# pma_rx_lane_registers: IP-XACT component
VLNV cadence:cdns_lib:pma_rx_lane_registers:1685-2009

## Address spaces and blocks
sd3101_t4_registers.sd3101_phy_registers: base 0x20000, range 0x7ff, width 32

## Registers
Registers are 32-bit, read-write, reset 0x0 unless marked. A register's access mark holds for its fields unless they carry their own. Offsets are from the block's base; lines under a group give offsets from that group; [hi:lo] are bit positions; {n}, {i} and the like mark numbered series; 'fields as' and 'values as' point back to an identical list; <NAME> marks a mode.

## sd3101_t4_registers.sd3101_phy_registers
Base 0x00020000
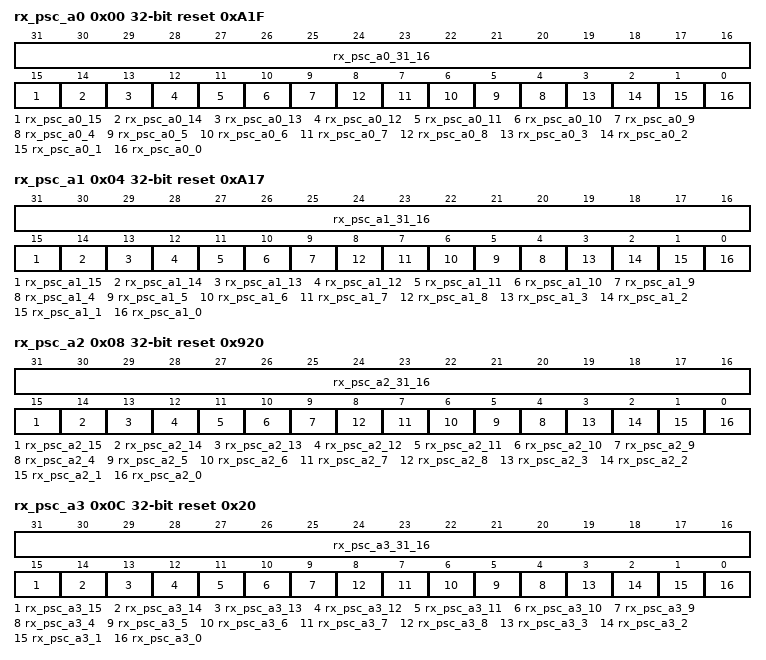
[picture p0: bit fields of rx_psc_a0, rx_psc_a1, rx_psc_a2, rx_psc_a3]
0x00 rx_psc_a0 reset 0xA1F — Receiver A0 power state definition register
  [31:16] rx_psc_a0_31_16 ro — Reserved
  [15] rx_psc_a0_15 ro — Reserved
  [14] rx_psc_a0_14 — rxda_dfe_error_threshold_pol
  [13] rx_psc_a0_13 — rxda_dfe_eq_tap1_pol
  [12] rx_psc_a0_12 — RX signal detect enable extend control
  [11] rx_psc_a0_11 — RX signal detect filter enable
  [10] rx_psc_a0_10
  [9] rx_psc_a0_9 — RX signal detect enable
  [n] rx_psc_a0_{n} (n=4..8) — rxda_dfe_eq_tap{n-3}_en
  [3] rx_psc_a0_3 — RX equalization functions enable
  [2] rx_psc_a0_2 — RX PI enable
  [1] rx_psc_a0_1 — RX e path enable
  [0] rx_psc_a0_0 — RX enable
0x04 rx_psc_a1 reset 0xA17 — Receiver A1 power state definition register
  [31:16] rx_psc_a1_31_16 ro — Reserved
  [15] rx_psc_a1_15 ro — Reserved
  [14] rx_psc_a1_14 — rxda_dfe_error_threshold_pol
  [13] rx_psc_a1_13 — rxda_dfe_eq_tap1_pol
  [12] rx_psc_a1_12 — RX signal detect enable extend control
  [11] rx_psc_a1_11 — RX signal detect filter enable
  [10] rx_psc_a1_10 — RX LFPS detect filter enable
  [9] rx_psc_a1_9 — RX signal detect enable
  [n] rx_psc_a1_{n} (n=4..8) — rxda_dfe_eq_tap{n-3}_en
  [3] rx_psc_a1_3 — RX equalization functions enable
  [2] rx_psc_a1_2 — RX PI enable
  [1] rx_psc_a1_1 — RX e path enable
  [0] rx_psc_a1_0 — RX enable
0x08 rx_psc_a2 reset 0x920 — Receiver A2 power state definition register
  [31:16] rx_psc_a2_31_16 ro — Reserved
  [15] rx_psc_a2_15 ro — Reserved
  [14] rx_psc_a2_14 — rxda_dfe_error_threshold_pol
  [13] rx_psc_a2_13 — rxda_dfe_eq_tap1_pol
  [12] rx_psc_a2_12 — RX signal detect enable extend control
  [11] rx_psc_a2_11 — RX signal detect filter enable
  [10] rx_psc_a2_10 — RX LFPS detect filter enable
  [9] rx_psc_a2_9 — RX signal detect enable
  [n] rx_psc_a2_{n} (n=4..8) — rxda_dfe_eq_tap{n-3}_en
  [3] rx_psc_a2_3 — RX equalization functions enable
  [2] rx_psc_a2_2 — RX PI enable
  [1] rx_psc_a2_1 — RX e path enable
  [0] rx_psc_a2_0 — RX enable
0x0C rx_psc_a3 reset 0x20 — Receiver A3 power state definition register
  [31:16] rx_psc_a3_31_16 ro — Reserved
  [15] rx_psc_a3_15 ro — Reserved
  [14] rx_psc_a3_14 — rxda_dfe_error_threshold_pol
  [13] rx_psc_a3_13 — rxda_dfe_eq_tap1_pol
  [12] rx_psc_a3_12 — RX signal detect enable extend control
  [11] rx_psc_a3_11 — RX signal detect filter enable
  [10] rx_psc_a3_10 — RX LFPS detect filter enable
  [9] rx_psc_a3_9 — RX signal detect enable
  [n] rx_psc_a3_{n} (n=4..8) — rxda_dfe_eq_tap{n-3}_en
  [3] rx_psc_a3_3 — RX equalization functions enable
  [2] rx_psc_a3_2 — RX PI enable
  [1] rx_psc_a3_1 — RX e path enable
  [0] rx_psc_a3_0 — RX enable
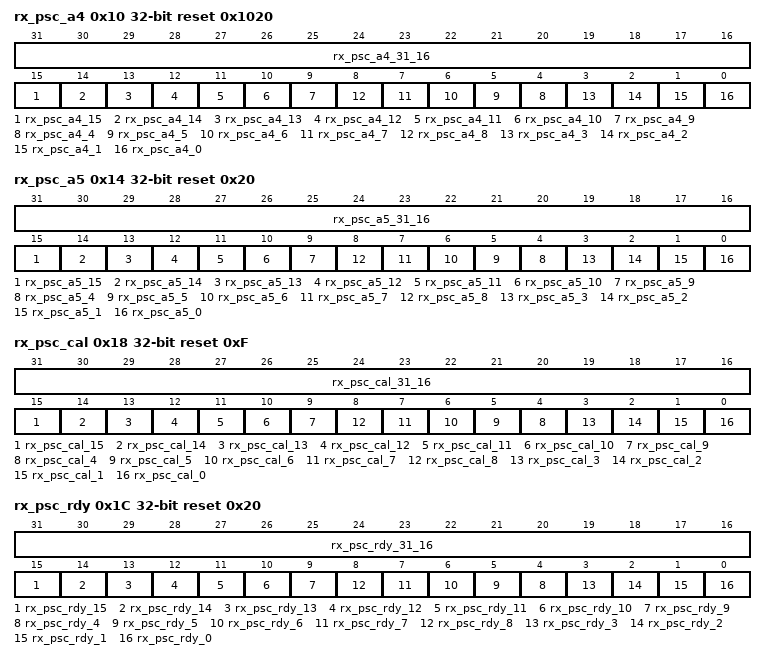
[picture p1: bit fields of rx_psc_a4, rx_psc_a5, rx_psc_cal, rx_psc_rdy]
0x10 rx_psc_a4 reset 0x1020 — Receiver A4 power state definition register
  [31:16] rx_psc_a4_31_16 ro — Reserved
  [15] rx_psc_a4_15 ro — Reserved
  [14] rx_psc_a4_14 — rxda_dfe_error_threshold_pol
  [13] rx_psc_a4_13 — rxda_dfe_eq_tap1_pol
  [12] rx_psc_a4_12 — RX signal detect enable extend control
  [11] rx_psc_a4_11 — RX signal detect filter enable
  [10] rx_psc_a4_10 — RX LFPS detect filter enable
  [9] rx_psc_a4_9 — RX signal detect enable
  [n] rx_psc_a4_{n} (n=4..8) — rxda_dfe_eq_tap{n-3}_en
  [3] rx_psc_a4_3 — RX equalization functions enable
  [2] rx_psc_a4_2 — RX PI enable
  [1] rx_psc_a4_1 — RX e path enable
  [0] rx_psc_a4_0 — RX enable
0x14 rx_psc_a5 reset 0x20 — Receiver A5 power state definition register
  [31:16] rx_psc_a5_31_16 ro — Reserved
  [15] rx_psc_a5_15 ro — Reserved
  [14] rx_psc_a5_14 — rxda_dfe_error_threshold_pol
  [13] rx_psc_a5_13 — rxda_dfe_eq_tap1_pol
  [12] rx_psc_a5_12 — RX signal detect enable extend control
  [11] rx_psc_a5_11 — RX signal detect filter enable
  [10] rx_psc_a5_10 — RX LFPS detect filter enable
  [9] rx_psc_a5_9 — RX signal detect enable
  [n] rx_psc_a5_{n} (n=4..8) — rxda_dfe_eq_tap{n-3}_en
  [3] rx_psc_a5_3 — RX equalization functions enable
  [2] rx_psc_a5_2 — RX PI enable
  [1] rx_psc_a5_1 — RX e path enable
  [0] rx_psc_a5_0 — RX enable
0x18 rx_psc_cal reset 0xF — Receiver calibration power state definition register
  [31:16] rx_psc_cal_31_16 ro — Reserved
  [15] rx_psc_cal_15 ro — Reserved
  [14] rx_psc_cal_14 — rxda_dfe_error_threshold_pol
  [13] rx_psc_cal_13 — rxda_dfe_eq_tap1_pol
  [12] rx_psc_cal_12 — RX signal detect enable extend control
  [11] rx_psc_cal_11 — RX signal detect filter enable
  [10] rx_psc_cal_10 — RX LFPS detect filter enable
  [9] rx_psc_cal_9 — RX signal detect enable
  [n] rx_psc_cal_{n} (n=4..8) — rxda_dfe_eq_tap{n-3}_en
  [3] rx_psc_cal_3 — RX equalization functions enable
  [2] rx_psc_cal_2 — RX PI enable
  [1] rx_psc_cal_1 — RX e path enable
  [0] rx_psc_cal_0 — RX enable
0x1C rx_psc_rdy reset 0x20 — Receiver ready power state definition register
  [31:16] rx_psc_rdy_31_16 ro — Reserved
  [15] rx_psc_rdy_15 ro — Reserved
  [14] rx_psc_rdy_14 — rxda_dfe_error_threshold_pol
  [13] rx_psc_rdy_13 — rxda_dfe_eq_tap1_pol
  [12] rx_psc_rdy_12 — RX signal detect enable extend control
  [11] rx_psc_rdy_11 — RX signal detect filter enable
  [10] rx_psc_rdy_10 — RX LFPS detect filter enable
  [9] rx_psc_rdy_9 — RX signal detect enable
  [n] rx_psc_rdy_{n} (n=4..8) — rxda_dfe_eq_tap{n-3}_en
  [3] rx_psc_rdy_3 — RX equalization functions enable
  [2] rx_psc_rdy_2 — RX PI enable
  [1] rx_psc_rdy_1 — RX e path enable
  [0] rx_psc_rdy_0 — RX enable
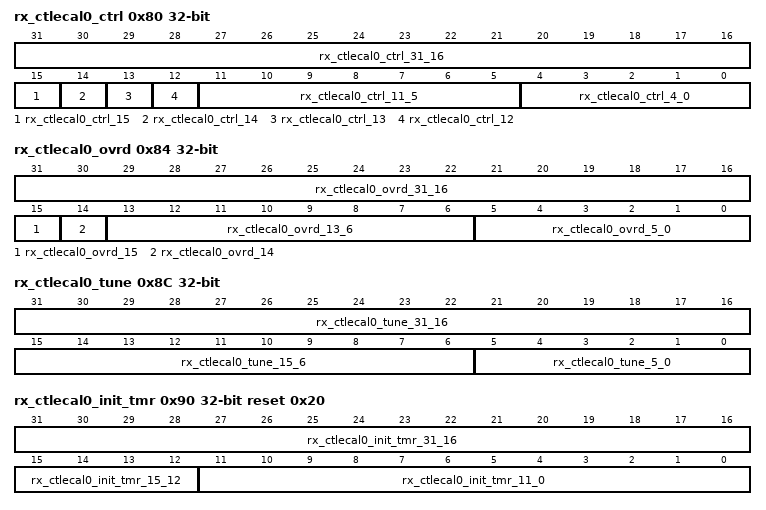
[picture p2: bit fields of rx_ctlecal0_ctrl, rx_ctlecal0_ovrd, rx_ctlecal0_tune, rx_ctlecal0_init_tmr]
0x80 rx_ctlecal0_ctrl — CTLE VGA offset calibration 0 control register
  [31:16] rx_ctlecal0_ctrl_31_16 ro — Reserved
  [15] rx_ctlecal0_ctrl_15 — Note: This bit is intended to be for diagnostics purposes only. This calibration process is automatically activated internally by the power state machine. When using this bit, the user must wait until after the internally activated process completes.
  [14] rx_ctlecal0_ctrl_14 ro — Note: Three cmn_ref_clk cycles are required after the start of the calibration process to clear this signal.
  [13] rx_ctlecal0_ctrl_13 ro — Note: Due to the nature of the calibration process, it is not possible to determine if the analog responded or not for the lowest code of 4'b1001. The reason for this is, when sequencing to lower codes, the calibration function is looking for the analog response to transition from 1'b1 to 1'b0. If the lowest calibration code is the correct code, the analog will respond with 1'b1, and the algorithm can't sequence to a lower code to look for the transition from 1'b1 to 1'b0. Similarly, if the analog is not responding, it is not possible to sequence to a lower code to detect this. Therefore, even when the calibration function selects this calibration code as valid, this bit will be set.
  [12] rx_ctlecal0_ctrl_12 ro
  [11:5] rx_ctlecal0_ctrl_11_5 ro — Reserved
  [4:0] rx_ctlecal0_ctrl_4_0 ro
0x84 rx_ctlecal0_ovrd — CTLE VGA offset calibration 0 override register
  [31:16] rx_ctlecal0_ovrd_31_16 ro — Reserved
  [15] rx_ctlecal0_ovrd_15 — Note: The value of this field must not be changed while the calibration function is running.
  [14] rx_ctlecal0_ovrd_14
  [13:6] rx_ctlecal0_ovrd_13_6 ro — Reserved
  [5:0] rx_ctlecal0_ovrd_5_0 — Note: The value of this field must not be changed while the calibration function is running.
0x8C rx_ctlecal0_tune — CTLE VGA offset calibration 0 tune register
  [31:16] rx_ctlecal0_tune_31_16 ro — Reserved
  [15:6] rx_ctlecal0_tune_15_6 ro — Reserved
  [5:0] rx_ctlecal0_tune_5_0 — Note: This value is a twos complement value, so the calibrated code can be increased or decreased.
0x90 rx_ctlecal0_init_tmr reset 0x20 — CTLE VGA offset calibration 0 initialization timer register
  [31:16] rx_ctlecal0_init_tmr_31_16 ro — Reserved
  [15:12] rx_ctlecal0_init_tmr_15_12 ro — Reserved
  [11:0] rx_ctlecal0_init_tmr_11_0 — Note: This results in the minimum number of cmn_ref_clk clocks required to wait 1 uSec. Note: This should never be set to a value of less than 1.
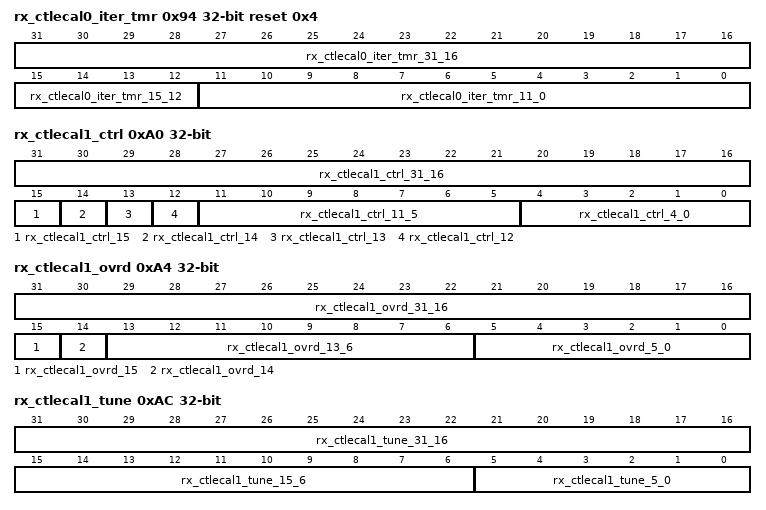
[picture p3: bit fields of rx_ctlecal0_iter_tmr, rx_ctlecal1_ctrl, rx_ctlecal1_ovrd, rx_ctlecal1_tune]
0x94 rx_ctlecal0_iter_tmr reset 0x4 — CTLE VGA offset calibration 0 iteration timer register
  [31:16] rx_ctlecal0_iter_tmr_31_16 ro — Reserved
  [15:12] rx_ctlecal0_iter_tmr_15_12 ro — Reserved
  [11:0] rx_ctlecal0_iter_tmr_11_0 — Note: This results in the minimum number of cmn_ref_clk clocks required to wait 5 uSec. Note: This should never be set to a value of less than 3.
0xA0 rx_ctlecal1_ctrl — CTLE VGA offset calibration 1 control register
  [31:16] rx_ctlecal1_ctrl_31_16 ro — Reserved
  [15] rx_ctlecal1_ctrl_15 — Note: This bit is intended to be for diagnostics purposes only. This calibration process is automatically activated internally by the power state machine. When using this bit, the user must wait until after the internally activated process completes.
  [14] rx_ctlecal1_ctrl_14 ro — Note: Three cmn_ref_clk cycles are required after the start of the calibration process to clear this signal.
  [13] rx_ctlecal1_ctrl_13 ro — Note: Due to the nature of the calibration process, it is not possible to determine if the analog responded or not for the lowest code of 4'b1001. The reason for this is, when sequencing to lower codes, the calibration function is looking for the analog response to transition from 1'b1 to 1'b0. If the lowest calibration code is the correct code, the analog will respond with 1'b1, and the algorithm can't sequence to a lower code to look for the transition from 1'b1 to 1'b0. Similarly, if the analog is not responding, it is not possible to sequence to a lower code to detect this. Therefore, even when the calibration function selects this calibration code as valid, this bit will be set.
  [12] rx_ctlecal1_ctrl_12 ro
  [11:5] rx_ctlecal1_ctrl_11_5 ro — Reserved
  [4:0] rx_ctlecal1_ctrl_4_0 ro
0xA4 rx_ctlecal1_ovrd — CTLE VGA offset calibration 1 override register
  [31:16] rx_ctlecal1_ovrd_31_16 ro — Reserved
  [15] rx_ctlecal1_ovrd_15 — Note: The value of this field must not be changed while the calibration function is running.
  [14] rx_ctlecal1_ovrd_14
  [13:6] rx_ctlecal1_ovrd_13_6 ro — Reserved
  [5:0] rx_ctlecal1_ovrd_5_0 — Note: The value of this field must not be changed while the calibration function is running.
0xAC rx_ctlecal1_tune — CTLE VGA offset calibration 1 tune register
  [31:16] rx_ctlecal1_tune_31_16 ro — Reserved
  [15:6] rx_ctlecal1_tune_15_6 ro — Reserved
  [5:0] rx_ctlecal1_tune_5_0 — Note: This value is a twos complement value, so the calibrated code can be increased or decreased.
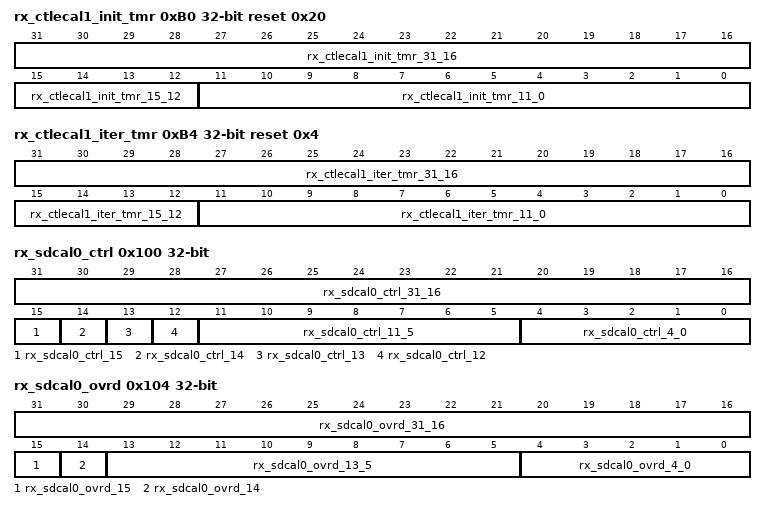
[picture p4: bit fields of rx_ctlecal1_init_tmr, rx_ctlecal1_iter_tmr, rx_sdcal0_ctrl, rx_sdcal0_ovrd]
0xB0 rx_ctlecal1_init_tmr reset 0x20 — CTLE VGA offset calibration 1 initialization timer register
  [31:16] rx_ctlecal1_init_tmr_31_16 ro — Reserved
  [15:12] rx_ctlecal1_init_tmr_15_12 ro — Reserved
  [11:0] rx_ctlecal1_init_tmr_11_0 — Note: This results in the minimum number of cmn_ref_clk clocks required to wait 1 uSec. Note: This should never be set to a value of less than 1.
0xB4 rx_ctlecal1_iter_tmr reset 0x4 — CTLE VGA offset calibration 1 iteration timer register
  [31:16] rx_ctlecal1_iter_tmr_31_16 ro — Reserved
  [15:12] rx_ctlecal1_iter_tmr_15_12 ro — Reserved
  [11:0] rx_ctlecal1_iter_tmr_11_0 — Note: This results in the minimum number of cmn_ref_clk clocks required to wait 5 uSec. Note: This should never be set to a value of less than 3.
0x100 rx_sdcal0_ctrl — Signal detect calibration 0 control register
  [31:16] rx_sdcal0_ctrl_31_16 ro — Reserved
  [15] rx_sdcal0_ctrl_15 — Note: This bit is intended to be for diagnostics purposes only. This calibration process is automatically activated internally by the power state machine. When using this bit, the user must wait until after the internally activated process completes.
  [14] rx_sdcal0_ctrl_14 ro — Note: Three cmn_ref_clk cycles are required after the start of the calibration process to clear this signal.
  [13] rx_sdcal0_ctrl_13 ro — Note: Due to the nature of the calibration process, it is not possible to determine if the analog responded or not for the lowest code of 4'b1001. The reason for this is, when sequencing to lower codes, the calibration function is looking for the analog response to transition from 1'b1 to 1'b0. If the lowest calibration code is the correct code, the analog will respond with 1'b1, and the algorithm can't sequence to a lower code to look for the transition from 1'b1 to 1'b0. Similarly, if the analog is not responding, it is not possible to sequence to a lower code to detect this. Therefore, even when the calibration function selects this calibration code as valid, this bit will be set.
  [12] rx_sdcal0_ctrl_12 ro
  [11:5] rx_sdcal0_ctrl_11_5 ro — Reserved
  [4:0] rx_sdcal0_ctrl_4_0 ro
0x104 rx_sdcal0_ovrd — Signal detect calibration 0 override register
  [31:16] rx_sdcal0_ovrd_31_16 ro — Reserved
  [15] rx_sdcal0_ovrd_15 — Note: The value of this field must not be changed while the calibration function is running.
  [14] rx_sdcal0_ovrd_14
  [13:5] rx_sdcal0_ovrd_13_5 ro — Reserved
  [4:0] rx_sdcal0_ovrd_4_0 — Note: The value of this field must not be changed while the calibration function is running.
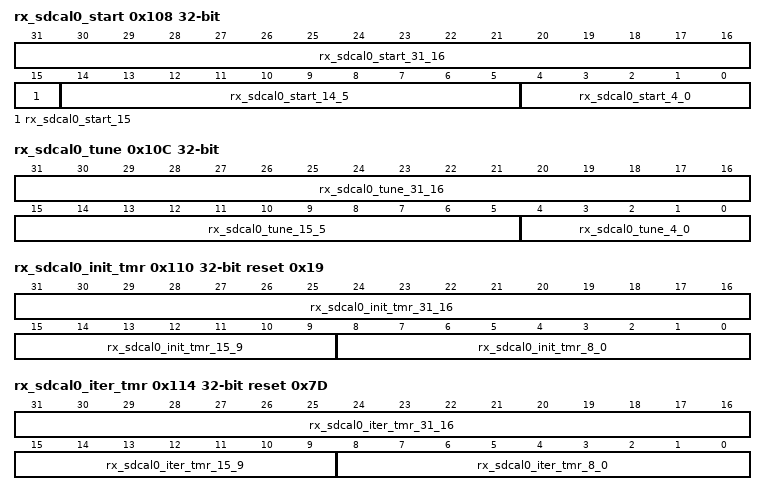
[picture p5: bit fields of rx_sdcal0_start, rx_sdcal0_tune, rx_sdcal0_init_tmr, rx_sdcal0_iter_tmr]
0x108 rx_sdcal0_start — Signal detect calibration 0 start register
  [31:16] rx_sdcal0_start_31_16 ro — Reserved
  [15] rx_sdcal0_start_15
  [14:5] rx_sdcal0_start_14_5 ro — Reserved
  [4:0] rx_sdcal0_start_4_0 — Start calibration code
0x10C rx_sdcal0_tune — Signal detect calibration 0 tune register
  [31:16] rx_sdcal0_tune_31_16 ro — Reserved
  [15:5] rx_sdcal0_tune_15_5 ro — Reserved
  [4:0] rx_sdcal0_tune_4_0 — Note: This value is a twos complement value, so the calibrated code can be increased or decreased.
0x110 rx_sdcal0_init_tmr reset 0x19 — Signal detect calibration 0 initialization timer register
  [31:16] rx_sdcal0_init_tmr_31_16 ro — Reserved
  [15:9] rx_sdcal0_init_tmr_15_9 ro — Reserved
  [8:0] rx_sdcal0_init_tmr_8_0 — Note: This results in the minimum number of cmn_ref_clk clocks required to wait 1 uSec. Note: This should never be set to a value of less than 1.
0x114 rx_sdcal0_iter_tmr reset 0x7D — Signal detect calibration 0 iteration timer register
  [31:16] rx_sdcal0_iter_tmr_31_16 ro — Reserved
  [15:9] rx_sdcal0_iter_tmr_15_9 ro — Reserved
  [8:0] rx_sdcal0_iter_tmr_8_0 — Note: This results in the minimum number of cmn_ref_clk clocks required to wait 5 uSec. Note: This should never be set to a value of less than 3.
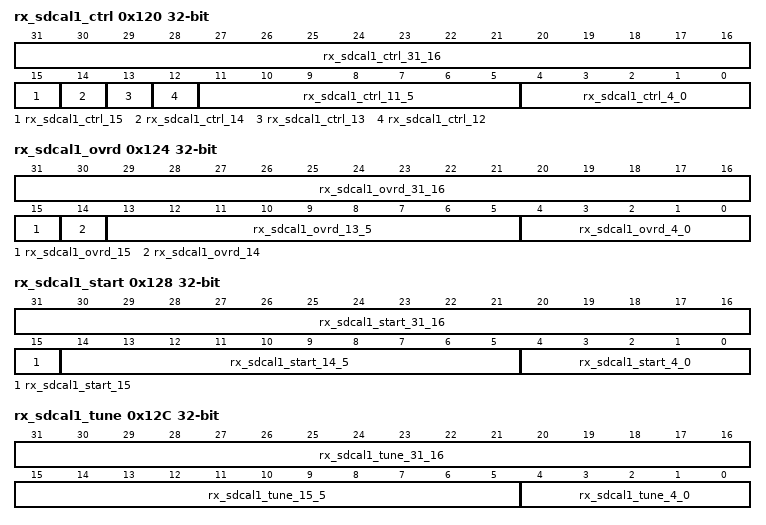
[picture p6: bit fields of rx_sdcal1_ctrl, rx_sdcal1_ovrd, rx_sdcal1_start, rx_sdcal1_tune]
0x120 rx_sdcal1_ctrl — Signal detect calibration 1 control register
  [31:16] rx_sdcal1_ctrl_31_16 ro — Reserved
  [15] rx_sdcal1_ctrl_15 — Note: This bit is intended to be for diagnostics purposes only. This calibration process is automatically activated internally by the power state machine. When using this bit, the user must wait until after the internally activated process completes.
  [14] rx_sdcal1_ctrl_14 ro — Note: Three cmn_ref_clk cycles are required after the start of the calibration process to clear this signal.
  [13] rx_sdcal1_ctrl_13 ro — Note: Due to the nature of the calibration process, it is not possible to determine if the analog responded or not for the lowest code of 4'b1001. The reason for this is, when sequencing to lower codes, the calibration function is looking for the analog response to transition from 1'b1 to 1'b0. If the lowest calibration code is the correct code, the analog will respond with 1'b1, and the algorithm can't sequence to a lower code to look for the transition from 1'b1 to 1'b0. Similarly, if the analog is not responding, it is not possible to sequence to a lower code to detect this. Therefore, even when the calibration function selects this calibration code as valid, this bit will be set.
  [12] rx_sdcal1_ctrl_12 ro
  [11:5] rx_sdcal1_ctrl_11_5 ro — Reserved
  [4:0] rx_sdcal1_ctrl_4_0 ro
0x124 rx_sdcal1_ovrd — Signal detect calibration 1 override register
  [31:16] rx_sdcal1_ovrd_31_16 ro — Reserved
  [15] rx_sdcal1_ovrd_15 — Note: The value of this field must not be changed while the calibration function is running.
  [14] rx_sdcal1_ovrd_14
  [13:5] rx_sdcal1_ovrd_13_5 ro — Reserved
  [4:0] rx_sdcal1_ovrd_4_0 — Note: The value of this field must not be changed while the calibration function is running.
0x128 rx_sdcal1_start — Signal detect calibration 1 start register
  [31:16] rx_sdcal1_start_31_16 ro — Reserved
  [15] rx_sdcal1_start_15
  [14:5] rx_sdcal1_start_14_5 ro — Reserved
  [4:0] rx_sdcal1_start_4_0 — Start calibration code
0x12C rx_sdcal1_tune — Signal detect calibration 1 tune register
  [31:16] rx_sdcal1_tune_31_16 ro — Reserved
  [15:5] rx_sdcal1_tune_15_5 ro — Reserved
  [4:0] rx_sdcal1_tune_4_0 — Note: This value is a twos complement value, so the calibrated code can be increased or decreased.
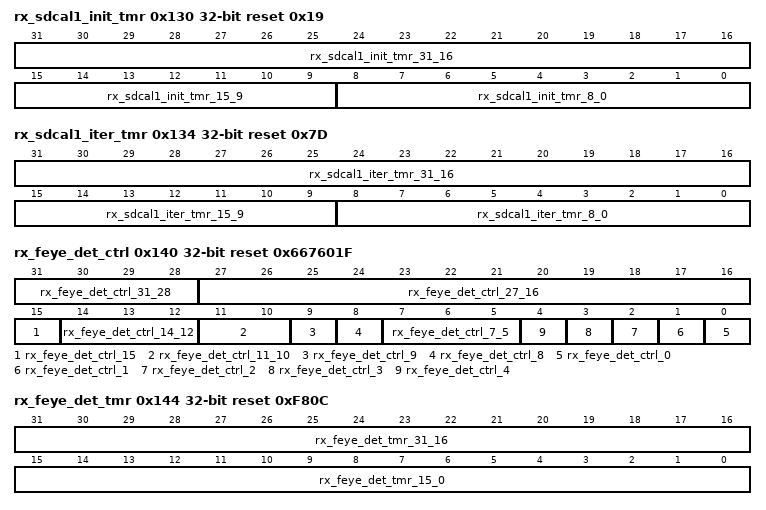
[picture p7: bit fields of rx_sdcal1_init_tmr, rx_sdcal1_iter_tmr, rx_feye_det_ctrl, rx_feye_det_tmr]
0x130 rx_sdcal1_init_tmr reset 0x19 — Signal detect calibration 1 initialization timer register
  [31:16] rx_sdcal1_init_tmr_31_16 ro — Reserved
  [15:9] rx_sdcal1_init_tmr_15_9 ro — Reserved
  [8:0] rx_sdcal1_init_tmr_8_0 — Note: This results in the minimum number of cmn_ref_clk clocks required to wait 1 uSec. Note: This should never be set to a value of less than 1.
0x134 rx_sdcal1_iter_tmr reset 0x7D — Signal detect calibration 1 iteration timer register
  [31:16] rx_sdcal1_iter_tmr_31_16 ro — Reserved
  [15:9] rx_sdcal1_iter_tmr_15_9 ro — Reserved
  [8:0] rx_sdcal1_iter_tmr_8_0 — Note: This results in the minimum number of cmn_ref_clk clocks required to wait 5 uSec. Note: This should never be set to a value of less than 3.
0x140 rx_feye_det_ctrl reset 0x667601F — RX false eye detect control register
  [31:28] rx_feye_det_ctrl_31_28 ro — Reserved
  [27:16] rx_feye_det_ctrl_27_16 — Threshold counter value
  [15] rx_feye_det_ctrl_15 ro — Reserved
  [14:12] rx_feye_det_ctrl_14_12 — Bandwidth
  [11:10] rx_feye_det_ctrl_11_10 ro — Reserved
  [9] rx_feye_det_ctrl_9 — Clear false eye detected
  [8] rx_feye_det_ctrl_8 ro
  [7:5] rx_feye_det_ctrl_7_5 ro — Reserved
  [n] rx_feye_det_ctrl_{n} (n=0..4)
0x144 rx_feye_det_tmr reset 0xF80C — RX false eye detect timer register
  [31:16] rx_feye_det_tmr_31_16 ro — Reserved
  [15:0] rx_feye_det_tmr_15_0
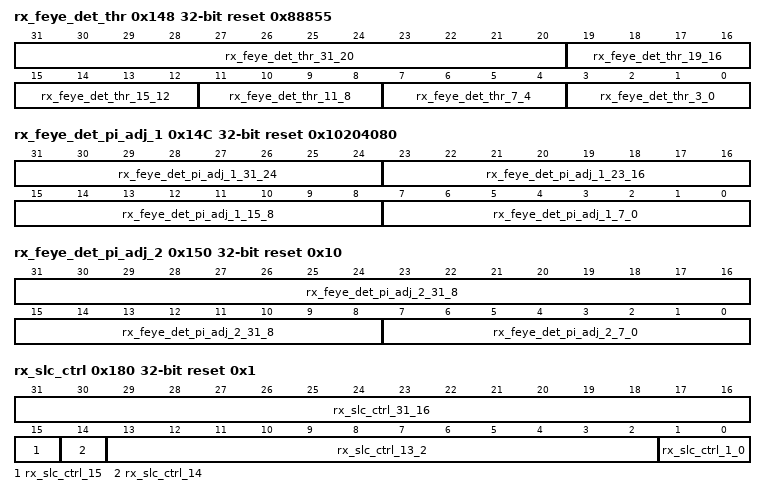
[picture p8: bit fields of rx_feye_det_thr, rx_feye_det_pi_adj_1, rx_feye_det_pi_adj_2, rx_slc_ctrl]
0x148 rx_feye_det_thr reset 0x88855 — RX false eye detect threshold register
  [31:20] rx_feye_det_thr_31_20 ro — Reserved
  [19:16] rx_feye_det_thr_19_16 — Threshold value standard mode 4
  [15:12] rx_feye_det_thr_15_12
  [11:8] rx_feye_det_thr_11_8 — Threshold value standard mode 2
  [7:4] rx_feye_det_thr_7_4 — Threshold value standard mode 1
  [3:0] rx_feye_det_thr_3_0
0x14C rx_feye_det_pi_adj_1 reset 0x10204080 — RX false eye detect PI adjust register 1
  [31:24] rx_feye_det_pi_adj_1_31_24 — PI adjust count standard mode 3
  [23:16] rx_feye_det_pi_adj_1_23_16
  [15:8] rx_feye_det_pi_adj_1_15_8 — PI adjust count standard mode 1
  [7:0] rx_feye_det_pi_adj_1_7_0 — PI adjust count standard mode 0
0x150 rx_feye_det_pi_adj_2 reset 0x10 — RX false eye detect PI adjust register 2
  [31:8] rx_feye_det_pi_adj_2_31_8 ro — Reserved
  [7:0] rx_feye_det_pi_adj_2_7_0 — PI adjust count standard mode 4
0x180 rx_slc_ctrl reset 0x1 — RX sampler latch calibration control register (!)
  [31:16] rx_slc_ctrl_31_16 — Reserved
  [15] rx_slc_ctrl_15
  [14] rx_slc_ctrl_14 ro
  [13:2] rx_slc_ctrl_13_2 ro — Reserved
  [1:0] rx_slc_ctrl_1_0
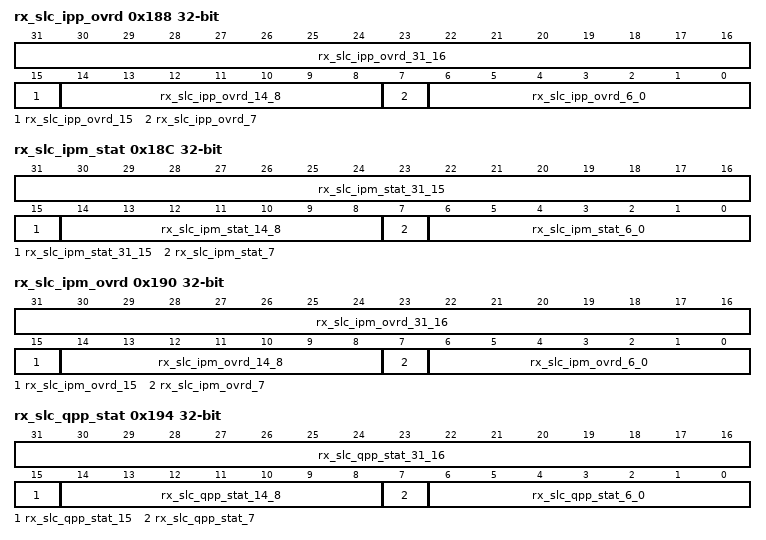
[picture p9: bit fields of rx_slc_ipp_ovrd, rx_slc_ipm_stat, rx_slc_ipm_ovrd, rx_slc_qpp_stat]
0x188 rx_slc_ipp_ovrd — RX sampler latch calibration I predictive positive override register (!)
  [31:16] rx_slc_ipp_ovrd_31_16 — Reserved
  [15] rx_slc_ipp_ovrd_15
  [14:8] rx_slc_ipp_ovrd_14_8 — Note: The value of this field is a signed magnitude number with a range of 5'b11111 (min) to 5'b01111 (max). A value of 5'b10000 (-0) is not valid.
  [7] rx_slc_ipp_ovrd_7
  [6:0] rx_slc_ipp_ovrd_6_0 — Note: The value of this field is a signed magnitude number with a range of 5'b11111 (min) to 5'b01111 (max). A value of 5'b10000 (-0) is not valid.
0x18C rx_slc_ipm_stat — RX sampler latch calibration I predictive negative status register
  [31:15] rx_slc_ipm_stat_31_15 ro — Reserved
  [14:8] rx_slc_ipm_stat_14_8 ro
  [7] rx_slc_ipm_stat_7 ro — Reserved
  [6:0] rx_slc_ipm_stat_6_0 ro
0x190 rx_slc_ipm_ovrd — RX sampler latch calibration I predictive negative override register
  [31:16] rx_slc_ipm_ovrd_31_16 ro — Reserved
  [15] rx_slc_ipm_ovrd_15
  [14:8] rx_slc_ipm_ovrd_14_8 — Note: The value of this field is a signed magnitude number with a range of 5'b11111 (min) to 5'b01111 (max). A value of 5'b10000 (-0) is not valid.
  [7] rx_slc_ipm_ovrd_7
  [6:0] rx_slc_ipm_ovrd_6_0 — Note: The value of this field is a signed magnitude number with a range of 5'b11111 (min) to 5'b01111 (max). A value of 5'b10000 (-0) is not valid.
0x194 rx_slc_qpp_stat — RX sampler latch calibration Q predictive positive status register
  [31:16] rx_slc_qpp_stat_31_16 ro — Reserved
  [15] rx_slc_qpp_stat_15 ro — Reserved
  [14:8] rx_slc_qpp_stat_14_8 ro
  [7] rx_slc_qpp_stat_7 ro — Reserved
  [6:0] rx_slc_qpp_stat_6_0 ro
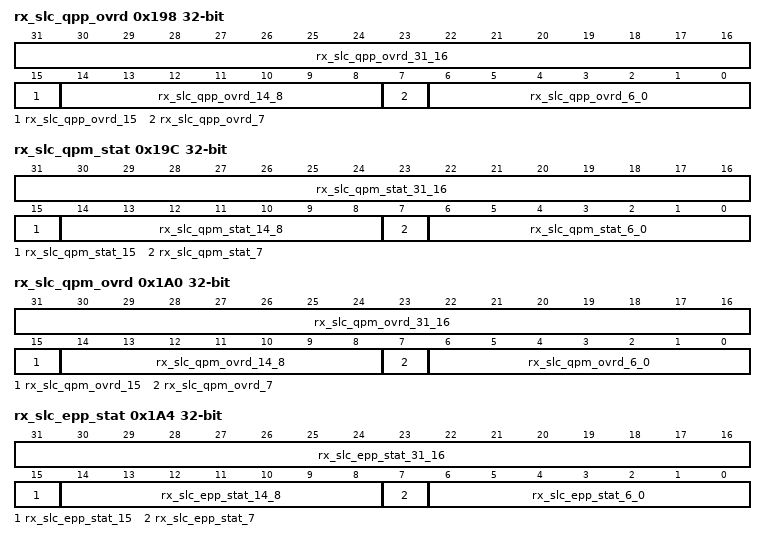
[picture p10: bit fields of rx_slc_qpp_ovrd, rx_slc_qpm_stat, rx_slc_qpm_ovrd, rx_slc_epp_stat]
0x198 rx_slc_qpp_ovrd — RX sampler latch calibration Q predictive positive override register
  [31:16] rx_slc_qpp_ovrd_31_16 ro — Reserved
  [15] rx_slc_qpp_ovrd_15
  [14:8] rx_slc_qpp_ovrd_14_8 — Note: The value of this field is a signed magnitude number with a range of 5'b11111 (min) to 5'b01111 (max). A value of 5'b10000 (-0) is not valid.
  [7] rx_slc_qpp_ovrd_7
  [6:0] rx_slc_qpp_ovrd_6_0 — Note: The value of this field is a signed magnitude number with a range of 5'b11111 (min) to 5'b01111 (max). A value of 5'b10000 (-0) is not valid.
0x19C rx_slc_qpm_stat — RX sampler latch calibration Q predictive negative status register
  [31:16] rx_slc_qpm_stat_31_16 ro — Reserved
  [15] rx_slc_qpm_stat_15 ro — Reserved
  [14:8] rx_slc_qpm_stat_14_8 ro
  [7] rx_slc_qpm_stat_7 ro — Reserved
  [6:0] rx_slc_qpm_stat_6_0 ro
0x1A0 rx_slc_qpm_ovrd — RX sampler latch calibration Q predictive negative override register
  [31:16] rx_slc_qpm_ovrd_31_16 ro — Reserved
  [15] rx_slc_qpm_ovrd_15
  [14:8] rx_slc_qpm_ovrd_14_8 — Note: The value of this field is a signed magnitude number with a range of 5'b11111 (min) to 5'b01111 (max). A value of 5'b10000 (-0) is not valid.
  [7] rx_slc_qpm_ovrd_7
  [6:0] rx_slc_qpm_ovrd_6_0 — Note: The value of this field is a signed magnitude number with a range of 5'b11111 (min) to 5'b01111 (max). A value of 5'b10000 (-0) is not valid.
0x1A4 rx_slc_epp_stat — RX sampler latch calibration e predictive positive status register
  [31:16] rx_slc_epp_stat_31_16 ro — Reserved
  [15] rx_slc_epp_stat_15 ro — Reserved
  [14:8] rx_slc_epp_stat_14_8 ro
  [7] rx_slc_epp_stat_7 ro — Reserved
  [6:0] rx_slc_epp_stat_6_0 ro
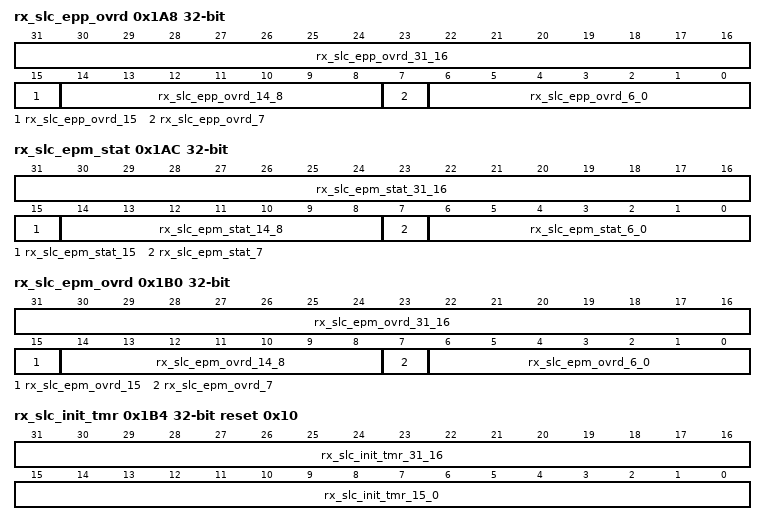
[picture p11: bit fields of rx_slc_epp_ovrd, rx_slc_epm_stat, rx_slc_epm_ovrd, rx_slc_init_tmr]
0x1A8 rx_slc_epp_ovrd — RX sampler latch calibration e predictive positive override register
  [31:16] rx_slc_epp_ovrd_31_16 ro — Reserved
  [15] rx_slc_epp_ovrd_15
  [14:8] rx_slc_epp_ovrd_14_8 — Note: The value of this field is a signed magnitude number with a range of 5'b11111 (min) to 5'b01111 (max). A value of 5'b10000 (-0) is not valid.
  [7] rx_slc_epp_ovrd_7
  [6:0] rx_slc_epp_ovrd_6_0 — Note: The value of this field is a signed magnitude number with a range of 5'b11111 (min) to 5'b01111 (max). A value of 5'b10000 (-0) is not valid.
0x1AC rx_slc_epm_stat — RX sampler latch calibration e predictive negative status register
  [31:16] rx_slc_epm_stat_31_16 ro — Reserved
  [15] rx_slc_epm_stat_15 ro — Reserved
  [14:8] rx_slc_epm_stat_14_8 ro
  [7] rx_slc_epm_stat_7 ro — Reserved
  [6:0] rx_slc_epm_stat_6_0 ro
0x1B0 rx_slc_epm_ovrd — RX sampler latch calibration e predictive negative override register
  [31:16] rx_slc_epm_ovrd_31_16 ro — Reserved
  [15] rx_slc_epm_ovrd_15
  [14:8] rx_slc_epm_ovrd_14_8 — Note: The value of this field is a signed magnitude number with a range of 5'b11111 (min) to 5'b01111 (max). A value of 5'b10000 (-0) is not valid.
  [7] rx_slc_epm_ovrd_7
  [6:0] rx_slc_epm_ovrd_6_0 — Note: The value of this field is a signed magnitude number with a range of 5'b11111 (min) to 5'b01111 (max). A value of 5'b10000 (-0) is not valid.
0x1B4 rx_slc_init_tmr reset 0x10 — RX sampler latch calibration initialization timer value register
  [31:16] rx_slc_init_tmr_31_16 ro — Reserved
  [15:0] rx_slc_init_tmr_15_0 — Note: This register should not be set to 16'h0000.
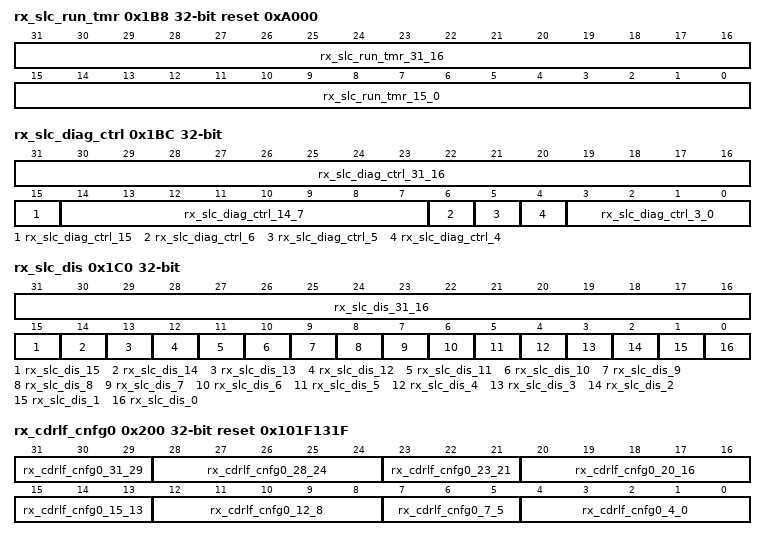
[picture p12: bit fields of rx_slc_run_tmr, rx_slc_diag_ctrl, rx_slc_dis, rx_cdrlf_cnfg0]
0x1B8 rx_slc_run_tmr reset 0xA000 — RX sampler latch calibration run timer value register
  [31:16] rx_slc_run_tmr_31_16 ro — Reserved
  [15:0] rx_slc_run_tmr_15_0 — Cadence internal note: The run timer value was changed to such a much longer time to allow for longer averaging, because of concerns the analog team has with regards to thermal noise. Significant variations of calibration codes were observed during lab characterization. It was shown in simulations that this was likely due to lower noise frequencies. Extending the run time has been shown to address the issue.
0x1BC rx_slc_diag_ctrl — RX sampler latch calibration diagnostic control register
  [31:16] rx_slc_diag_ctrl_31_16 ro — Reserved
  [15] rx_slc_diag_ctrl_15
  [14:7] rx_slc_diag_ctrl_14_7 ro — Reserved
  [6] rx_slc_diag_ctrl_6
  [5] rx_slc_diag_ctrl_5
  [4] rx_slc_diag_ctrl_4
  [3:0] rx_slc_diag_ctrl_3_0
0x1C0 rx_slc_dis — RX sampler latch calibration disable register
  [31:16] rx_slc_dis_31_16 ro — Reserved
  [15] rx_slc_dis_15 ro — Reserved
  [14] rx_slc_dis_14 — e even negative coefficient disable :
  [13] rx_slc_dis_13 — q even negative coefficient disable :
  [12] rx_slc_dis_12 — i even negative coefficient disable :
  [11] rx_slc_dis_11 ro — Reserved
  [10] rx_slc_dis_10 — e even positive coefficient disable :
  [9] rx_slc_dis_9 — q even positive coefficient disable :
  [8] rx_slc_dis_8 — i even positive coefficient disable :
  [7] rx_slc_dis_7 ro — Reserved
  [6] rx_slc_dis_6 — e odd negative coefficient disable :
  [5] rx_slc_dis_5 — q odd negative coefficient disable :
  [4] rx_slc_dis_4 — i odd negative coefficient disable :
  [3] rx_slc_dis_3 ro — Reserved
  [2] rx_slc_dis_2 — e odd positive coefficient disable :
  [1] rx_slc_dis_1 — q odd positive coefficient disable :
  [0] rx_slc_dis_0 — i odd positive coefficient disable :
0x200 rx_cdrlf_cnfg0 reset 0x101F131F — CDRLF configuration register 0
  [31:29] rx_cdrlf_cnfg0_31_29 ro — Reserved
  [28:24] rx_cdrlf_cnfg0_28_24 — CDRLF first order loop sigma delta update rate standard mode 3
  [23:21] rx_cdrlf_cnfg0_23_21 ro — Reserved
  [20:16] rx_cdrlf_cnfg0_20_16 — CDRLF first order loop sigma delta update rate standard mode 2
  [15:13] rx_cdrlf_cnfg0_15_13 ro — Reserved
  [12:8] rx_cdrlf_cnfg0_12_8 — CDRLF first order loop sigma delta update rate standard mode 1
  [7:5] rx_cdrlf_cnfg0_7_5 ro — Reserved
  [4:0] rx_cdrlf_cnfg0_4_0 — CDRLF first order loop sigma delta update rate standard mode 0
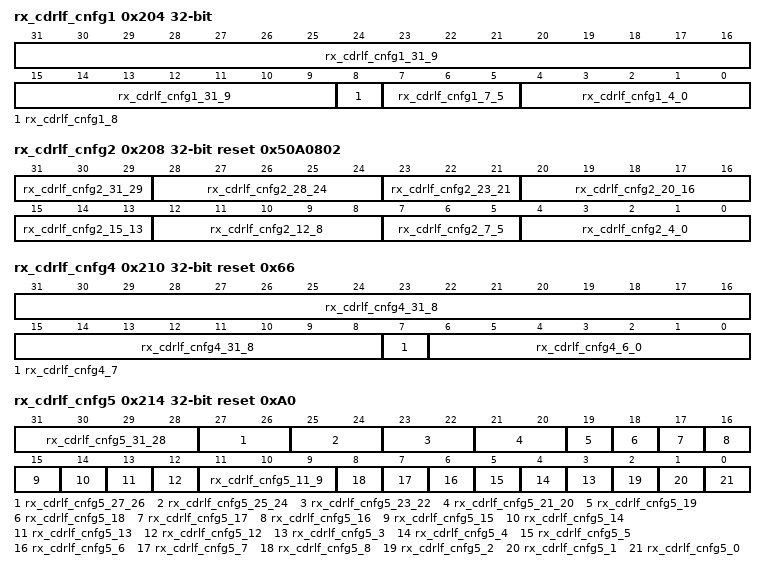
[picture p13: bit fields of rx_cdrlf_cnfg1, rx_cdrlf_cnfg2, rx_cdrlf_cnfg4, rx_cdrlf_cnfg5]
0x204 rx_cdrlf_cnfg1 — CDRLF configuration register 1
  [31:9] rx_cdrlf_cnfg1_31_9 ro — Reserved
  [8] rx_cdrlf_cnfg1_8 — rxda_iq_offset_load_pulse :
  [7:5] rx_cdrlf_cnfg1_7_5 ro — Reserved
  [4:0] rx_cdrlf_cnfg1_4_0
0x208 rx_cdrlf_cnfg2 reset 0x50A0802 — CDRLF configuration register 2
  [31:29] rx_cdrlf_cnfg2_31_29 ro — Reserved
  [28:24] rx_cdrlf_cnfg2_28_24
  [23:21] rx_cdrlf_cnfg2_23_21 ro — Reserved
  [20:16] rx_cdrlf_cnfg2_20_16 — CDRLF second order loop sigma delta update rate standard mode 2
  [15:13] rx_cdrlf_cnfg2_15_13 ro — Reserved
  [12:8] rx_cdrlf_cnfg2_12_8 — CDRLF second order loop sigma delta update rate standard mode 1
  [7:5] rx_cdrlf_cnfg2_7_5 ro — Reserved
  [4:0] rx_cdrlf_cnfg2_4_0
0x210 rx_cdrlf_cnfg4 reset 0x66 — CDRLF configuration register 4
  [31:8] rx_cdrlf_cnfg4_31_8 ro — Reserved
  [7] rx_cdrlf_cnfg4_7 ro — Reserved
  [6:0] rx_cdrlf_cnfg4_6_0 — Note: This field must never be set to a value less than 2 (6'b000010).
0x214 rx_cdrlf_cnfg5 reset 0xA0 — Note: Writing this register will result in wait states, in order to allow the values to be propagated to and sampled in the analog.
  [31:28] rx_cdrlf_cnfg5_31_28 ro — Reserved
  [27:26] rx_cdrlf_cnfg5_27_26
  [25:24] rx_cdrlf_cnfg5_25_24
  [23:22] rx_cdrlf_cnfg5_23_22
  [21:20] rx_cdrlf_cnfg5_21_20
  [19] rx_cdrlf_cnfg5_19 ro — Reserved
  [18] rx_cdrlf_cnfg5_18 wo — Note : This bit will be automatically cleared after the down request has been sent to the CDRLF IQ PI inter- face logic. The down request is generated by changing the state of the cdrlf_pi_down_in signal in the CDRLF.
  [17] rx_cdrlf_cnfg5_17 wo — Note : This bit will be automatically cleared after the up request has been sent to the CDRLF IQ PI interface logic. The up request is generated by changing the state of the cdrlf_pi_up_in signal in the CDRLF.
  [16] rx_cdrlf_cnfg5_16
  [15] rx_cdrlf_cnfg5_15 ro — Reserved
  [14] rx_cdrlf_cnfg5_14 wo — Note : This bit will be automatically cleared after the down request has been sent to the CDRLF PI inter- face logic.
  [13] rx_cdrlf_cnfg5_13 wo — Note : This bit will be automatically cleared after the up request has been sent to the CDRLF PI interface logic.
  [12] rx_cdrlf_cnfg5_12
  [11:9] rx_cdrlf_cnfg5_11_9 ro — Reserved
  [n] rx_cdrlf_cnfg5_{n} (n=3..8)
  [2] rx_cdrlf_cnfg5_2 — Note: This signal is intended be for verification purposes only. It should be set to 1'b0 for normal operation.
  [1] rx_cdrlf_cnfg5_1 — Note: This signal is intended be for verification purposes only. It should be set to 1'b0 for normal operation.
  [0] rx_cdrlf_cnfg5_0 — Note: This signal is intended be for verification purposes only. It should be set to 1'b0 for normal operation.
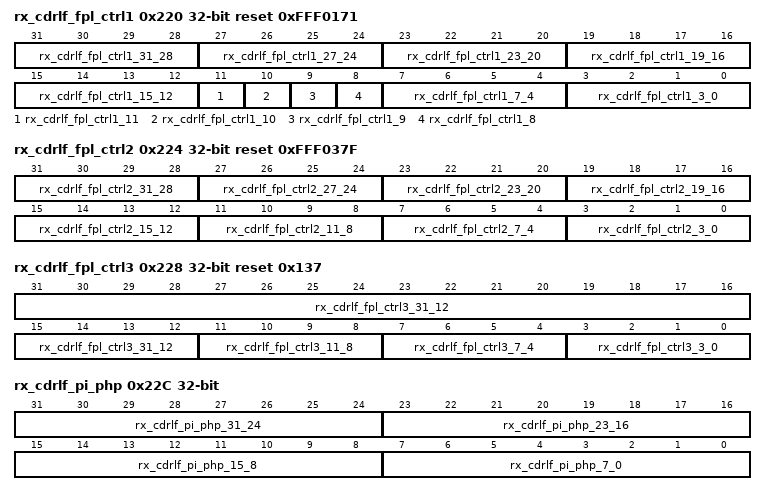
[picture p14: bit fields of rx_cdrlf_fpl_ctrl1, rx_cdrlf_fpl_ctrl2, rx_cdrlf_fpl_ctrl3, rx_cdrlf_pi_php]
0x220 rx_cdrlf_fpl_ctrl1 reset 0xFFF0171 — CDRLF fast phase lock control 1 register
  [31:28] rx_cdrlf_fpl_ctrl1_31_28 ro — Reserved
  [27:24] rx_cdrlf_fpl_ctrl1_27_24 — Fast phase lock timer trigger 3 state time value standard mode 0
  [23:20] rx_cdrlf_fpl_ctrl1_23_20 — Fast phase lock timer trigger 2 state time value standard mode 0
  [19:16] rx_cdrlf_fpl_ctrl1_19_16 — Fast phase lock timer trigger 1 state time value standard mode 0
  [15:12] rx_cdrlf_fpl_ctrl1_15_12 ro — Reserved
  [11] rx_cdrlf_fpl_ctrl1_11 ro — Reserved
  [10] rx_cdrlf_fpl_ctrl1_10 ro — CDRLF fast phase lock locked detected:
  [9] rx_cdrlf_fpl_ctrl1_9
  [8] rx_cdrlf_fpl_ctrl1_8 — CDRLF fast phase lock enabled by signal detect
  [7:4] rx_cdrlf_fpl_ctrl1_7_4 — Fast phase lock timer accumulate state time value
  [3:0] rx_cdrlf_fpl_ctrl1_3_0 — Fast phase lock timer delay state time value
0x224 rx_cdrlf_fpl_ctrl2 reset 0xFFF037F — CDRLF fast phase lock control 2 register
  [31:28] rx_cdrlf_fpl_ctrl2_31_28 ro — Reserved
  [27:24] rx_cdrlf_fpl_ctrl2_27_24
  [23:20] rx_cdrlf_fpl_ctrl2_23_20
  [19:16] rx_cdrlf_fpl_ctrl2_19_16
  [15:12] rx_cdrlf_fpl_ctrl2_15_12 ro — Reserved
  [11:8] rx_cdrlf_fpl_ctrl2_11_8
  [7:4] rx_cdrlf_fpl_ctrl2_7_4
  [3:0] rx_cdrlf_fpl_ctrl2_3_0
0x228 rx_cdrlf_fpl_ctrl3 reset 0x137 — CDRLF fast phase lock control 3 register
  [31:12] rx_cdrlf_fpl_ctrl3_31_12 ro — Reserved
  [11:8] rx_cdrlf_fpl_ctrl3_11_8
  [7:4] rx_cdrlf_fpl_ctrl3_7_4
  [3:0] rx_cdrlf_fpl_ctrl3_3_0
0x22C rx_cdrlf_pi_php — Note: The information read in this register is retrieved from another clock domain. Reading this register will result in wait states, in order to allow the control and data to cross the clock domains and be stable such that it can be accurately read.
  [31:24] rx_cdrlf_pi_php_31_24 ro — Reserved
  [23:16] rx_cdrlf_pi_php_23_16 ro — I PI phase position value
  [15:8] rx_cdrlf_pi_php_15_8 ro — Q PI phase position value
  [7:0] rx_cdrlf_pi_php_7_0 ro — E PI phase position value
0x230 rx_cdrlf_2ol_gain — Note: The information read in this register is retrieved from another clock domain. Reading this register will result in wait states, in order to allow the control and data to cross the clock domains and be stable such that it can be accurately read.
  [31:16] rx_cdrlf_2ol_gain_31_16 ro — Reserved
  [15:8] rx_cdrlf_2ol_gain_15_8 ro — Reserved
  [7:0] rx_cdrlf_2ol_gain_7_0 ro — Second order loop gain value
0x280 rx_eyesurf_ctrl — Eye surf control register
  [31] rx_eyesurf_ctrl_31
  [30] rx_eyesurf_ctrl_30 ro — Eye surf done
  [29:28] rx_eyesurf_ctrl_29_28 ro — Reserved
  [27:26] rx_eyesurf_ctrl_27_26 ro — Reserved
  [25] rx_eyesurf_ctrl_25 — Reserved - Spare
  [24] rx_eyesurf_ctrl_24
  [23:16] rx_eyesurf_ctrl_23_16 — Note : It is not valid to set this field to 0.
  [15:8] rx_eyesurf_ctrl_15_8 ro — Reserved
  [7:2] rx_eyesurf_ctrl_7_2 ro — Reserved
  [1] rx_eyesurf_ctrl_1
  [0] rx_eyesurf_ctrl_0
0x284 rx_eyesurf_tmr_test — Eye surf timer test register
  [31:0] rx_eyesurf_tmr_test_31_0 — Note : It is not valid to set this field to 0.
0x288 rx_eyesurf_offset — Eye surf test point offset register
  [31:17] rx_eyesurf_offset_31_17 ro — Reserved
  [16] rx_eyesurf_offset_16
  [15:9] rx_eyesurf_offset_15_9 ro — Reserved
  [8:0] rx_eyesurf_offset_8_0 — Test point coordinate east west offset
0x28C rx_eyesurf_errcnt — Eye surf bit error count register
  [31:16] rx_eyesurf_errcnt_31_16 ro — Reserved
  [15:0] rx_eyesurf_errcnt_15_0 ro
0x300 rx_qcccal_ctrl — QCC calibration control register
  [31:16] rx_qcccal_ctrl_31_16 ro — Reserved
  [15] rx_qcccal_ctrl_15 — Note: This bit is intended to be for diagnostics purposes only. This calibration process is automatically activated internally by the power state machine. When using this bit, the user must wait until after the internally activated process completes.
  [14] rx_qcccal_ctrl_14 ro — Note: Three cmn_ref_clk cycles are required after the start of the calibration process to clear this signal.
  [13] rx_qcccal_ctrl_13 ro — Note: Due to the nature of the calibration process, it is not possible to determine if the analog responded or not for the lowest code of 4'b1001. The reason for this is, when sequencing to lower codes, the calibration function is looking for the analog response to transition from 1'b1 to 1'b0. If the lowest calibration code is the correct code, the analog will respond with 1'b1, and the algorithm can't sequence to a lower code to look for the transition from 1'b1 to 1'b0. Similarly, if the analog is not responding, it is not possible to sequence to a lower code to detect this. Therefore, even when the calibration function selects this calibration code as valid, this bit will be set.
  [12] rx_qcccal_ctrl_12 ro
  [11:5] rx_qcccal_ctrl_11_5 ro — Reserved
  [4:0] rx_qcccal_ctrl_4_0 ro
0x304 rx_qcccal_ovrd — QCC calibration override register
  [31:16] rx_qcccal_ovrd_31_16 ro — Reserved
  [15] rx_qcccal_ovrd_15 — Note: The value of this field must not be changed while the calibration function is running.
  [14] rx_qcccal_ovrd_14
  [13:5] rx_qcccal_ovrd_13_5 ro — Reserved
  [4:0] rx_qcccal_ovrd_4_0 — Note: The value of this field must not be changed while the calibration function is running.
0x308 rx_qcccal_start — QCC calibration 0 start register
  [31:16] rx_qcccal_start_31_16 ro — Reserved
  [15] rx_qcccal_start_15
  [14:5] rx_qcccal_start_14_5 ro — Reserved
  [4:0] rx_qcccal_start_4_0 — QCC calibration 0 control register
0x30C rx_qcccal_tune — QCC calibration tune register
  [31:16] rx_qcccal_tune_31_16 ro — Reserved
  [15:5] rx_qcccal_tune_15_5 ro — Reserved
  [4:0] rx_qcccal_tune_4_0 — Note: This value is a twos complement value, so the calibrated code can be increased or decreased.
0x310 rx_qcccal_init_tmr reset 0x19 — QCC calibration initialization timer register
  [31:16] rx_qcccal_init_tmr_31_16 ro — Reserved
  [15:9] rx_qcccal_init_tmr_15_9 ro — Reserved
  [8:0] rx_qcccal_init_tmr_8_0 — Note: This results in the minimum number of cmn_ref_clk clocks required to wait 1 uSec. Note: This should never be set to a value of less than 1.
0x314 rx_qcccal_iter_tmr reset 0x7D — QCC calibration iteration timer register
  [31:16] rx_qcccal_iter_tmr_31_16 ro — Reserved
  [15:9] rx_qcccal_iter_tmr_15_9 ro — Reserved
  [8:0] rx_qcccal_iter_tmr_8_0 — Note: This results in the minimum number of cmn_ref_clk clocks required to wait 5 uSec. Note: This should never be set to a value of less than 3.
0x700 xcvr_cmsmt_clk_freq_msmt_ctrl — Clock frequency measurement control register
  [31:16] xcvr_cmsmt_clk_freq_msmt_ctrl_31_16 ro — Reserved
  [15] xcvr_cmsmt_clk_freq_msmt_ctrl_15 — Note: The values in the Test clock selection register and Reference clock timer value register must be set prior to activating this bit.
  [14] xcvr_cmsmt_clk_freq_msmt_ctrl_14 ro — Test clock measurement done
  [13:0] xcvr_cmsmt_clk_freq_msmt_ctrl_13_0 ro — Reserved
0x704 xcvr_cmsmt_test_clk_sel — Test clock selection register
  [31:16] xcvr_cmsmt_test_clk_sel_31_16 ro — Reserved
  [15:4] xcvr_cmsmt_test_clk_sel_15_4 ro — Reserved
  [3:0] xcvr_cmsmt_test_clk_sel_3_0
0x708 xcvr_cmsmt_ref_clk_tmr_value — Reference clock timer value register
  [31:16] xcvr_cmsmt_ref_clk_tmr_value_31_16 ro — Reserved
  [15:0] xcvr_cmsmt_ref_clk_tmr_value_15_0 — clock cycles. This value minus 1 is loaded into the reference clock timer. A value of 0 for this field is not valid when running this function.
0x70C xcvr_cmsmt_test_clk_cnt_value — Test clock counter value register
  [31:16] xcvr_cmsmt_test_clk_cnt_value_31_16 ro — Reserved
  [15:0] xcvr_cmsmt_test_clk_cnt_value_15_0 ro — Test clock counter value: When the test clock measurement process is complete, the value in this field specifies the number of test clock cycles that were counted in the time specified by the reference clock timer value. This field is only valid while the test clock measurement done bit in the Clock frequency measurement control register is active.
0x7D4 rx_diag_xcvr_rate_sel reset 0x4500 — Reserved
  [15:14] rx_diag_xcvr_rate_sel_15_14
  [13:12] rx_diag_xcvr_rate_sel_13_12
  [11:10] rx_diag_xcvr_rate_sel_11_10 — config 01 in usb3
  [9:8] rx_diag_xcvr_rate_sel_9_8 — config 00 in usb3
  [5:4] rx_diag_xcvr_rate_sel_5_4 — xcvrda_ratesel_iqgen
  [2] rx_diag_xcvr_rate_sel_2 — sd_clk_bypass
  [1] rx_diag_xcvr_rate_sel_1 — fe_offset_range_low
  [0] rx_diag_xcvr_rate_sel_0 — atb_en
